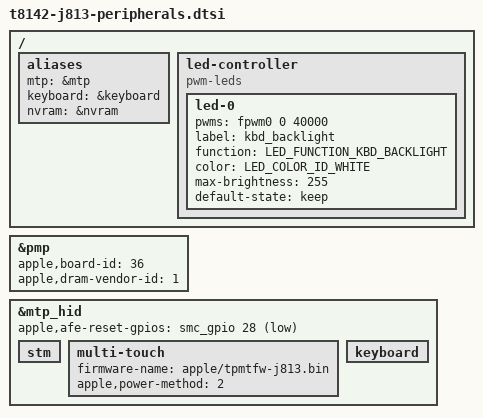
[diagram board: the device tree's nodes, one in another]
// SPDX-License-Identifier: GPL-2.0+ OR MIT
#include <dt-bindings/gpio/gpio.h>
#include <dt-bindings/leds/common.h>

/ {
	aliases {
		mtp = &mtp;
		keyboard = &keyboard;
		nvram = &nvram;
	};

	led-controller {
		compatible = "pwm-leds";

		led-0 {
			pwms = <&fpwm0 0 40000>;
			label = "kbd_backlight";
			function = LED_FUNCTION_KBD_BACKLIGHT;
			color = <LED_COLOR_ID_WHITE>;
			max-brightness = <255>;
			default-state = "keep";
		};
	};
};

&pmp {
	/* ADT /chosen board-id, dram-vendor-id */
	apple,board-id = <36>;
	apple,dram-vendor-id = <1>;
};

&mtp_hid {
	/*
	 * ADT dockchannel-mtp/mtp-transport/multi-touch:
	 * function-afe-reset = smc-pmu pKW4('gP1c'), SMC GPIO 28.
	 * The MTP firmware cannot reach the AFE on its own ("No
	 * HINT_L"): after macOS left it running the trackpad
	 * worked, after a Linux warm reboot it stayed in reset.
	 */
	apple,afe-reset-gpios = <&smc_gpio 28 GPIO_ACTIVE_LOW>;

	stm { };

	multi-touch {
		firmware-name = "apple/tpmtfw-j813.bin";
		apple,power-method = <2>;
	};

	/* Layout is filled by the loader using this machine's own data. */
	keyboard: keyboard { };
};

#include "t8142-j813-pmp-tunables.dtsi"
